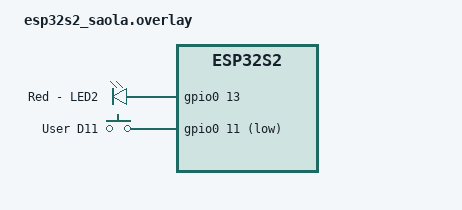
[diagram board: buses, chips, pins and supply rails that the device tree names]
/ {
    aliases {
      led0 = &red_led;
      sw0 = &user_button_d11;
    };
    leds {
      compatible = "gpio-leds";
      red_led: led_2 {
        gpios = <&gpio0 13 GPIO_ACTIVE_HIGH>;
        label = "Red - LED2";
      };
    };
    gpio_keys {
      compatible = "gpio-keys";
      user_button_d11: button_0 {
        label = "User D11";
        gpios = <&gpio0 11 (GPIO_ACTIVE_LOW | GPIO_PULL_UP)>;
      };
    };
};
